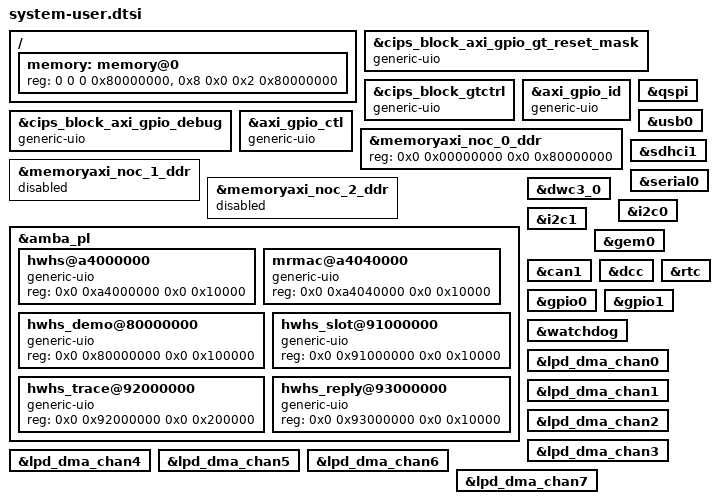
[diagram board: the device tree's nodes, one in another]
// SPDX-License-Identifier: Apache-2.0
// Copyright 2026 Xanadu Quantum Technologies Inc.
//
// backline-roce: what the ERNIC build's system-user.dtsi had, minus ERNIC (no reserved
// memory, no xib/kmm/pl_allocator, no axienet MRMAC node), plus the PL windows the
// hwhs userspace driver maps through UIO (vpk-init binds "generic-uio" devices). The same
// windows as the HSB build.

&cips_block_axi_gpio_gt_reset_mask {
	compatible = "generic-uio";
};
&cips_block_gtctrl {
	compatible = "generic-uio";
};
&cips_block_axi_gpio_debug {
	compatible = "generic-uio";
};
&axi_gpio_id {
	compatible = "generic-uio";
};
&axi_gpio_ctl {
	compatible = "generic-uio";
};

// Linux uses the 2 GB of DDR_LOW0, as before; the other two LPDDR4 triplets stay unused.
&memoryaxi_noc_0_ddr {
	reg = <0x0 0x00000000 0x0 0x80000000>;
};
&memoryaxi_noc_1_ddr {
	status = "disabled";
};
&memoryaxi_noc_2_ddr {
	status = "disabled";
};

&amba_pl {
	// BD external ports have no generated node; the BRAM windows get their own so the
	// mapping does not depend on which of their two addresses the generator picks.
	hwhs@a4000000 {
		compatible = "generic-uio";
		reg = <0x0 0xa4000000 0x0 0x10000>;
	};
	mrmac@a4040000 {
		compatible = "generic-uio";
		reg = <0x0 0xa4040000 0x0 0x10000>;
	};
	hwhs_demo@80000000 {
		compatible = "generic-uio";
		reg = <0x0 0x80000000 0x0 0x100000>;
	};
	hwhs_slot@91000000 {
		compatible = "generic-uio";
		reg = <0x0 0x91000000 0x0 0x10000>;
	};
	hwhs_trace@92000000 {
		compatible = "generic-uio";
		reg = <0x0 0x92000000 0x0 0x200000>;
	};
	hwhs_reply@93000000 {
		compatible = "generic-uio";
		reg = <0x0 0x93000000 0x0 0x10000>;
	};
};

// Keep last. re-includes versal.dtsi (resetting every PS status to "disabled"), 
// then the VPK120 board fragment, memory@0 and the enables below.
#include "versal.dtsi"
#include "versal-clk.dtsi"
#include "versal-vpk120-revb.dtsi"

/ {
	memory: memory@0 {
		device_type = "memory";
		reg = <0 0 0 0x80000000>, <0x8 0x0 0x2 0x80000000>;
	};
};

&qspi { status = "okay"; };
&usb0 { status = "okay"; };
&dwc3_0 { status = "okay"; };
&sdhci1 { status = "okay"; };
&serial0 { status = "okay"; };
&i2c0 { status = "okay"; };
&i2c1 { status = "okay"; };
&gem0 { status = "okay"; };
&can1 { status = "okay"; };
&dcc { status = "okay"; };
&rtc { status = "okay"; };
&gpio0 { status = "okay"; };
&gpio1 { status = "okay"; };
&watchdog { status = "okay"; };
&lpd_dma_chan0 { status = "okay"; };
&lpd_dma_chan1 { status = "okay"; };
&lpd_dma_chan2 { status = "okay"; };
&lpd_dma_chan3 { status = "okay"; };
&lpd_dma_chan4 { status = "okay"; };
&lpd_dma_chan5 { status = "okay"; };
&lpd_dma_chan6 { status = "okay"; };
&lpd_dma_chan7 { status = "okay"; };
